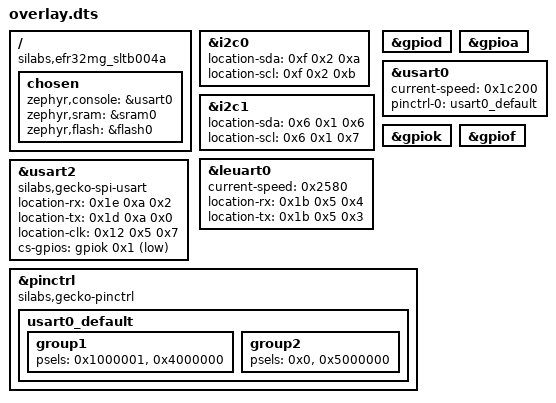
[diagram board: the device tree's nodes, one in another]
/ {
	compatible = "silabs,efr32mg_sltb004a", "silabs,efr32mg";
	chosen {
		zephyr,console = &usart0;
		zephyr,sram = &sram0;
		zephyr,flash = &flash0;
	};
};
&i2c0{
	status = "okay";
	location-sda = < 0xf 0x2 0xa >;
	location-scl = < 0xf 0x2 0xb >;
};
&i2c1{
	status = "okay";
	location-sda = < 0x6 0x1 0x6 >;
	location-scl = < 0x6 0x1 0x7 >;
};
&gpiod{
	status = "okay";
};
&gpioa{
	status = "okay";
};
&leuart0{
	status = "okay";
	current-speed = < 0x2580 >;
	location-rx = < 0x1b 0x5 0x4 >;
	location-tx = < 0x1b 0x5 0x3 >;
};
&usart0{
	status = "okay";
	current-speed = < 0x1c200 >;
	pinctrl-0 = < &usart0_default >;
	pinctrl-names = "default";
};
&gpiok{
	status = "okay";
};
&gpiof{
	status = "okay";
};
&usart2{
	compatible = "silabs,gecko-spi-usart";
	status = "okay";
	#address-cells = < 0x1 >;
	#size-cells = < 0x0 >;
	location-rx = < 0x1e 0xa 0x2 >;
	location-tx = < 0x1d 0xa 0x0 >;
	location-clk = < 0x12 0x5 0x7 >;
	cs-gpios = < &gpiok 0x1 0x1 >;
};
&pinctrl{
	compatible = "silabs,gecko-pinctrl";
	usart0_default: usart0_default {
		group1 {
			psels = < 0x1000001 >, < 0x4000000 >;
		};
		group2 {
			psels = < 0x0 >, < 0x5000000 >;
		};
	};
};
